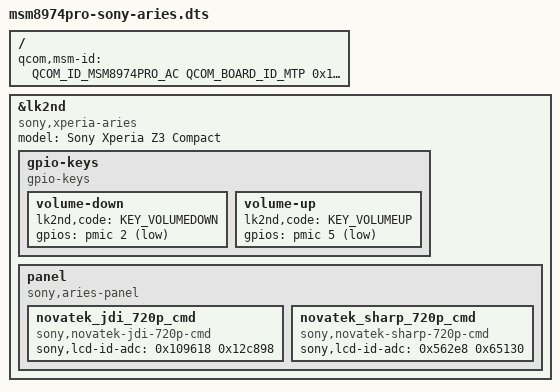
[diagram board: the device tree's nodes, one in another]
// SPDX-License-Identifier: GPL-2.0-only

#include <skeleton64.dtsi>
#include <lk2nd.dtsi>

/*
 * Because the bootloader uses parts of the dts to initialise the panel,
 * this isn't included with the other dts. To build, you need to add
 * LK2ND_QCDTBS="msm8974pro-sony-aries.dtb" to the build command.
 */

/ {
	qcom,msm-id = <QCOM_ID_MSM8974PRO_AC QCOM_BOARD_ID_MTP 0x10000>;
};

&lk2nd {
	model = "Sony Xperia Z3 Compact";
	compatible = "sony,xperia-aries";

	//FIXME: lk2nd,dtb-files = "msm8974pro-sony-aries";
	
	gpio-keys {
		compatible = "gpio-keys";
		
		volume-down {
			lk2nd,code = <KEY_VOLUMEDOWN>;
			gpios = <&pmic 2 (GPIO_ACTIVE_LOW | GPIO_PULL_UP)>;
		};
		
		volume-up {
			lk2nd,code = <KEY_VOLUMEUP>;
			gpios = <&pmic 5 (GPIO_ACTIVE_LOW | GPIO_PULL_UP)>;
		};
	};
	
	panel {
		compatible = "sony,aries-panel", "lk2nd,panel";
		
		novatek_jdi_720p_cmd {
			compatible = "sony,novatek-jdi-720p-cmd";
			sony,lcd-id-adc = <0x109618 0x12c898>;
		};
		
		novatek_sharp_720p_cmd {
			compatible = "sony,novatek-sharp-720p-cmd";
			sony,lcd-id-adc = <0x562e8 0x65130>;
		};
	};
};

#include "sony-aries/msm8974pro-ac-shinano_aries-display.dtsi"

